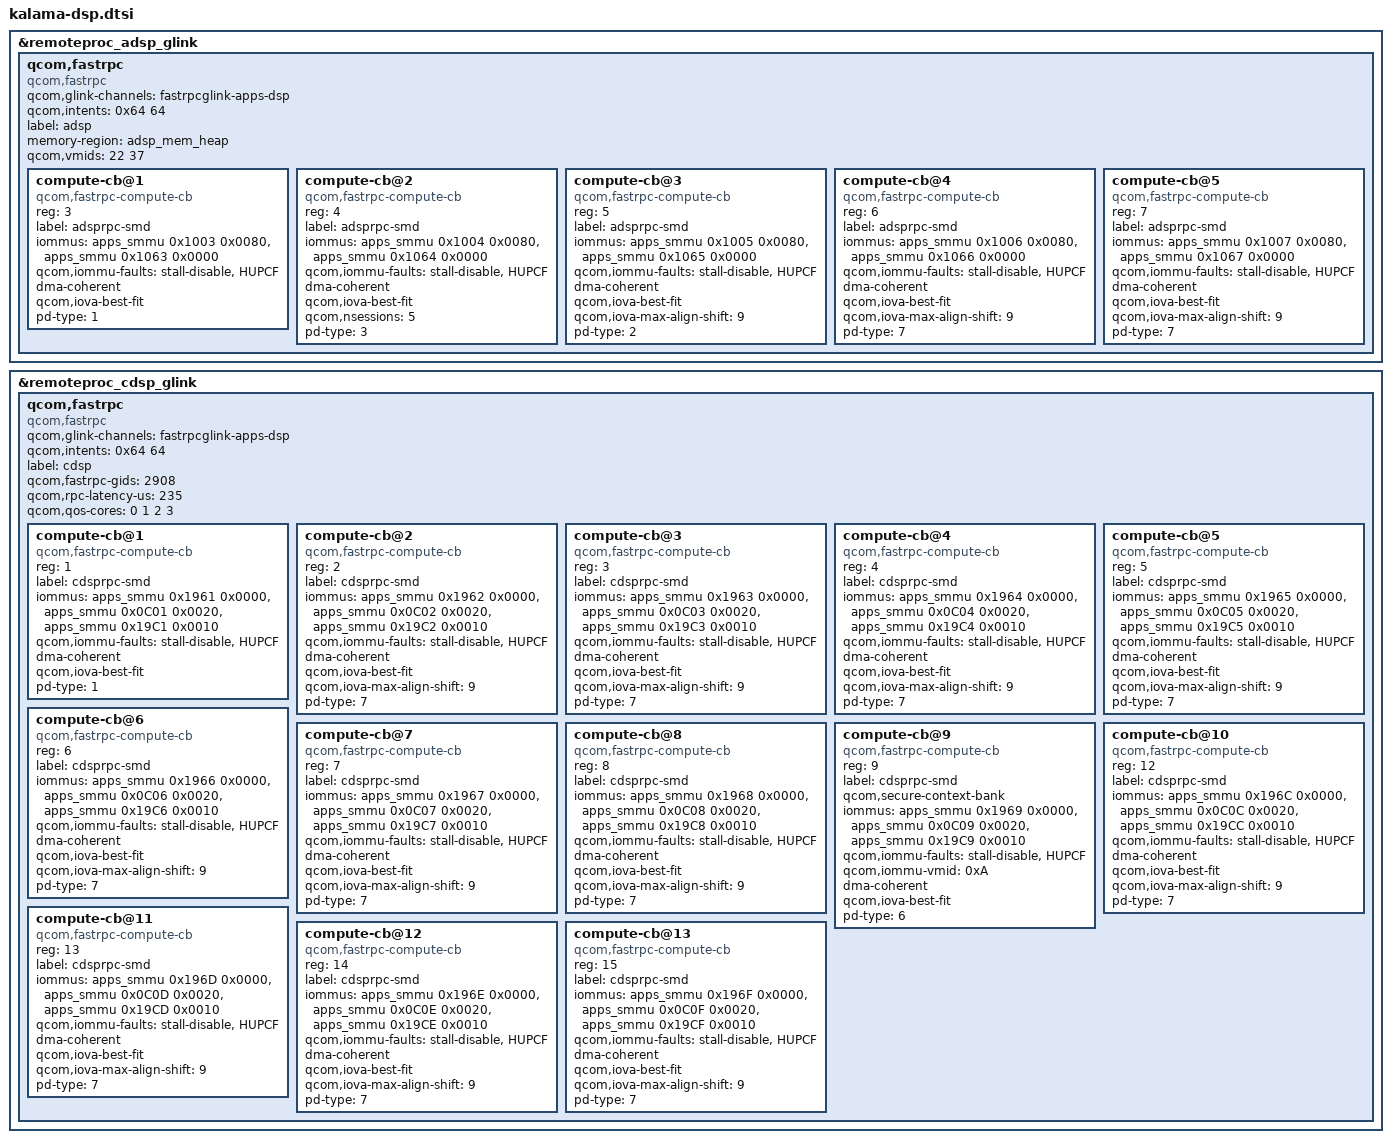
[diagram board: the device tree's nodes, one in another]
&remoteproc_adsp_glink {
	qcom,fastrpc {
		compatible = "qcom,fastrpc";
		qcom,glink-channels = "fastrpcglink-apps-dsp";
		qcom,intents = <0x64 64>;
		label = "adsp";
		memory-region = <&adsp_mem_heap>;
		qcom,vmids = <22 37>;

		#address-cells = <1>;
		#size-cells = <0>;

		compute-cb@1 {
			compatible = "qcom,fastrpc-compute-cb";
			reg = <3>;
			label = "adsprpc-smd";
			iommus = <&apps_smmu 0x1003 0x0080>,
				 <&apps_smmu 0x1063 0x0000>;
			qcom,iommu-faults = "stall-disable", "HUPCF";
			dma-coherent;
			qcom,iova-best-fit;
			pd-type = <1>; /* ROOT_PD */
		};

		compute-cb@2 {
			compatible = "qcom,fastrpc-compute-cb";
			reg = <4>;
			label = "adsprpc-smd";
			iommus = <&apps_smmu 0x1004 0x0080>,
				 <&apps_smmu 0x1064 0x0000>;
			qcom,iommu-faults = "stall-disable", "HUPCF";
			dma-coherent;
			qcom,iova-best-fit;
			qcom,nsessions = <5>;
			pd-type = <3>;	/* SENSORS_STATICPD */
		};

		compute-cb@3 {
			compatible = "qcom,fastrpc-compute-cb";
			reg = <5>;
			label = "adsprpc-smd";
			iommus = <&apps_smmu 0x1005 0x0080>,
				 <&apps_smmu 0x1065 0x0000>;
			qcom,iommu-faults = "stall-disable", "HUPCF";
			dma-coherent;
			qcom,iova-best-fit;
			qcom,iova-max-align-shift = <9>; /* Set MAX alignment to 2 MB */
			pd-type = <2>; /* AUDIO_STATICPD */
		};

		compute-cb@4 {
			compatible = "qcom,fastrpc-compute-cb";
			reg = <6>;
			label = "adsprpc-smd";
			iommus = <&apps_smmu 0x1006 0x0080>,
				 <&apps_smmu 0x1066 0x0000>;
			qcom,iommu-faults = "stall-disable", "HUPCF";
			dma-coherent;
			qcom,iova-best-fit;
			qcom,iova-max-align-shift = <9>; /* Set MAX alignment to 2 MB */
			pd-type = <7>; /* USERPD */
		};

		compute-cb@5 {
			compatible = "qcom,fastrpc-compute-cb";
			reg = <7>;
			label = "adsprpc-smd";
			iommus = <&apps_smmu 0x1007 0x0080>,
				 <&apps_smmu 0x1067 0x0000>;
			qcom,iommu-faults = "stall-disable", "HUPCF";
			dma-coherent;
			qcom,iova-best-fit;
			qcom,iova-max-align-shift = <9>; /* Set MAX alignment to 2 MB */
			pd-type = <7>; /* USERPD */
		};
	};
};

&remoteproc_cdsp_glink {
	qcom,fastrpc {
		compatible = "qcom,fastrpc";
		qcom,glink-channels = "fastrpcglink-apps-dsp";
		qcom,intents = <0x64 64>;
		label = "cdsp";
		qcom,fastrpc-gids = <2908>;
		qcom,rpc-latency-us = <235>;
		qcom,qos-cores = <0 1 2 3>;

		#address-cells = <1>;
		#size-cells = <0>;

		compute-cb@1 {
			compatible = "qcom,fastrpc-compute-cb";
			reg = <1>;
			label = "cdsprpc-smd";
			iommus = <&apps_smmu 0x1961 0x0000>,
				 <&apps_smmu 0x0C01 0x0020>,
				 <&apps_smmu 0x19C1 0x0010>;
			qcom,iommu-faults = "stall-disable", "HUPCF";
			dma-coherent;
			qcom,iova-best-fit;
			pd-type = <1>; /* ROOT_PD */
		};

		compute-cb@2 {
			compatible = "qcom,fastrpc-compute-cb";
			reg = <2>;
			label = "cdsprpc-smd";
			iommus = <&apps_smmu 0x1962 0x0000>,
				 <&apps_smmu 0x0C02 0x0020>,
				 <&apps_smmu 0x19C2 0x0010>;
			qcom,iommu-faults = "stall-disable", "HUPCF";
			dma-coherent;
			qcom,iova-best-fit;
			qcom,iova-max-align-shift = <9>; /* Set MAX alignment to 2 MB */
			pd-type = <7>; /* USERPD */
		};

		compute-cb@3 {
			compatible = "qcom,fastrpc-compute-cb";
			reg = <3>;
			label = "cdsprpc-smd";
			iommus = <&apps_smmu 0x1963 0x0000>,
				 <&apps_smmu 0x0C03 0x0020>,
				 <&apps_smmu 0x19C3 0x0010>;
			qcom,iommu-faults = "stall-disable", "HUPCF";
			dma-coherent;
			qcom,iova-best-fit;
			qcom,iova-max-align-shift = <9>; /* Set MAX alignment to 2 MB */
			pd-type = <7>; /* USERPD */
		};

		compute-cb@4 {
			compatible = "qcom,fastrpc-compute-cb";
			reg = <4>;
			label = "cdsprpc-smd";
			iommus = <&apps_smmu 0x1964 0x0000>,
				 <&apps_smmu 0x0C04 0x0020>,
				 <&apps_smmu 0x19C4 0x0010>;
			qcom,iommu-faults = "stall-disable", "HUPCF";
			dma-coherent;
			qcom,iova-best-fit;
			qcom,iova-max-align-shift = <9>; /* Set MAX alignment to 2 MB */
			pd-type = <7>; /* USERPD */
		};

		compute-cb@5 {
			compatible = "qcom,fastrpc-compute-cb";
			reg = <5>;
			label = "cdsprpc-smd";
			iommus = <&apps_smmu 0x1965 0x0000>,
				 <&apps_smmu 0x0C05 0x0020>,
				 <&apps_smmu 0x19C5 0x0010>;
			qcom,iommu-faults = "stall-disable", "HUPCF";
			dma-coherent;
			qcom,iova-best-fit;
			qcom,iova-max-align-shift = <9>; /* Set MAX alignment to 2 MB */
			pd-type = <7>; /* USERPD */
		};

		compute-cb@6 {
			compatible = "qcom,fastrpc-compute-cb";
			reg = <6>;
			label = "cdsprpc-smd";
			iommus = <&apps_smmu 0x1966 0x0000>,
				 <&apps_smmu 0x0C06 0x0020>,
				 <&apps_smmu 0x19C6 0x0010>;
			qcom,iommu-faults = "stall-disable", "HUPCF";
			dma-coherent;
			qcom,iova-best-fit;
			qcom,iova-max-align-shift = <9>; /* Set MAX alignment to 2 MB */
			pd-type = <7>; /* USERPD */
		};

		compute-cb@7 {
			compatible = "qcom,fastrpc-compute-cb";
			reg = <7>;
			label = "cdsprpc-smd";
			iommus = <&apps_smmu 0x1967 0x0000>,
				 <&apps_smmu 0x0C07 0x0020>,
				 <&apps_smmu 0x19C7 0x0010>;
			qcom,iommu-faults = "stall-disable", "HUPCF";
			dma-coherent;
			qcom,iova-best-fit;
			qcom,iova-max-align-shift = <9>; /* Set MAX alignment to 2 MB */
			pd-type = <7>; /* USERPD */
		};

		compute-cb@8 {
			compatible = "qcom,fastrpc-compute-cb";
			reg = <8>;
			label = "cdsprpc-smd";
			iommus = <&apps_smmu 0x1968 0x0000>,
				 <&apps_smmu 0x0C08 0x0020>,
				 <&apps_smmu 0x19C8 0x0010>;
			qcom,iommu-faults = "stall-disable", "HUPCF";
			dma-coherent;
			qcom,iova-best-fit;
			qcom,iova-max-align-shift = <9>; /* Set MAX alignment to 2 MB */
			pd-type = <7>; /* USERPD */
		};

		compute-cb@9 {
			compatible = "qcom,fastrpc-compute-cb";
			reg = <9>;
			label = "cdsprpc-smd";
			qcom,secure-context-bank;
			iommus = <&apps_smmu 0x1969 0x0000>,
				 <&apps_smmu 0x0C09 0x0020>,
				 <&apps_smmu 0x19C9 0x0010>;
			qcom,iommu-faults = "stall-disable", "HUPCF";
			qcom,iommu-vmid = <0xA>; /* VMID_CP_PIXEL */
			dma-coherent;
			qcom,iova-best-fit;
			pd-type = <6>; /* CPZ_USERPD */
		};

		compute-cb@10 {
			compatible = "qcom,fastrpc-compute-cb";
			reg = <12>;
			label = "cdsprpc-smd";
			iommus = <&apps_smmu 0x196C 0x0000>,
				 <&apps_smmu 0x0C0C 0x0020>,
				 <&apps_smmu 0x19CC 0x0010>;
			qcom,iommu-faults = "stall-disable", "HUPCF";
			dma-coherent;
			qcom,iova-best-fit;
			qcom,iova-max-align-shift = <9>; /* Set MAX alignment to 2 MB */
			pd-type = <7>; /* USERPD */
		};

		compute-cb@11 {
			compatible = "qcom,fastrpc-compute-cb";
			reg = <13>;
			label = "cdsprpc-smd";
			iommus = <&apps_smmu 0x196D 0x0000>,
				 <&apps_smmu 0x0C0D 0x0020>,
				 <&apps_smmu 0x19CD 0x0010>;
			qcom,iommu-faults = "stall-disable", "HUPCF";
			dma-coherent;
			qcom,iova-best-fit;
			qcom,iova-max-align-shift = <9>; /* Set MAX alignment to 2 MB */
			pd-type = <7>; /* USERPD */
		};

		compute-cb@12 {
			compatible = "qcom,fastrpc-compute-cb";
			reg = <14>;
			label = "cdsprpc-smd";
			iommus = <&apps_smmu 0x196E 0x0000>,
				 <&apps_smmu 0x0C0E 0x0020>,
				 <&apps_smmu 0x19CE 0x0010>;
			qcom,iommu-faults = "stall-disable", "HUPCF";
			dma-coherent;
			qcom,iova-best-fit;
			qcom,iova-max-align-shift = <9>; /* Set MAX alignment to 2 MB */
			pd-type = <7>; /* USERPD */
		};

		compute-cb@13 {
			compatible = "qcom,fastrpc-compute-cb";
			reg = <15>;
			label = "cdsprpc-smd";
			iommus = <&apps_smmu 0x196F 0x0000>,
				 <&apps_smmu 0x0C0F 0x0020>,
				 <&apps_smmu 0x19CF 0x0010>;
			qcom,iommu-faults = "stall-disable", "HUPCF";
			dma-coherent;
			qcom,iova-best-fit;
			qcom,iova-max-align-shift = <9>; /* Set MAX alignment to 2 MB */
			pd-type = <7>; /* USERPD */
		};
	};
};
